AUTOSAR XML (schema 00046)
package /MICROSAR/BswM_swc
  6 x mode declaration group, all with category=EXPLICIT_ORDER:
    ESH_RunRequest: initial-mode=RELEASED, on-transition-value=2
      mode RELEASED: value=0
      mode REQUESTED: value=1
    BswMRteShutdownReqMode: initial-mode=BswMReqNone, on-transition-value=5
      5 x mode:
        BswMReqSleep: value=1
        BswMReqShutdown: value=3
        BswMReqShutdownEmergency: value=4
        BswMReqNone: value=0
        BswMReqSleepEmergency: value=5
    ESH_Mode: initial-mode=STARTUP, on-transition-value=6
      6 x mode:
        STARTUP: value=0
        RUN: value=1
        POSTRUN: value=2
        WAKEUP: value=3
        SHUTDOWN: value=4
        NVMPROCESS: value=5
    BswMRteVehicleTypeOptionChoose: initial-mode=FUEL, on-transition-value=2
      mode FUEL: value=0
      mode EV: value=1
    BswMRteModeBusStateReq: initial-mode=BLOCK_STATE, on-transition-value=2
      mode BLOCK_STATE: value=1
      mode UNBLOCK_STATE: value=0
    BswMRteModeVolEnable: initial-mode=Vol_Disable, on-transition-value=2
      mode Vol_Disable: value=0
      mode Vol_Enable: value=1
  data type mapping set BswMMappingSet  # Contains Mapping for ModeDeclarations Groups which are provided by BswM.
    mode-request-type-maps:
      implementation-data-type=BswM_ESH_Mode, mode-group=ESH_Mode
      implementation-data-type=BswM_ESH_RunRequest, mode-group=ESH_RunRequest
      implementation-data-type=BswM_BswMRteShutdownReqMode, mode-group=BswMRteShutdownReqMode
      implementation-data-type=BswM_BswMRteVehicleTypeOptionChoose, mode-group=BswMRteVehicleTypeOptionChoose
      implementation-data-type=BswM_BswMRteModeBusStateReq, mode-group=BswMRteModeBusStateReq
      implementation-data-type=BswM_BswMRteModeVolEnable, mode-group=BswMRteModeVolEnable
package /MICROSAR/BswM_swc/DataTypes
  6 x impl type, all with category=TYPE_REFERENCE, range raw 0..255, implementation-data-type=uint8:
    BswM_ESH_RunRequest: compu {0=RELEASED, 1=REQUESTED}  # Unique value for each user
    BswM_BswMRteShutdownReqMode: compu {1=BswMReqSleep, 3=BswMReqShutdown, 4=BswMReqShutdownEmergency, 0=BswMReqNone, 5=BswMReqSleepEmergency}  # Unique value for each user
    BswM_ESH_Mode: compu {0=STARTUP, 1=RUN, 2=POSTRUN, 3=WAKEUP, 4=SHUTDOWN, 5=NVMPROCESS}  # Unique value for each user
    BswM_BswMRteVehicleTypeOptionChoose: compu {0=FUEL, 1=EV}  # Unique value for each user
    BswM_BswMRteModeBusStateReq: compu {1=BLOCK_STATE, 0=UNBLOCK_STATE}  # Unique value for each user
    BswM_BswMRteModeVolEnable: compu {0=Vol_Disable, 1=Vol_Enable}  # Unique value for each user
package /MICROSAR/BswM_swc/Interfaces
  mode switch interface BswM_MSI_ESH_Mode: is-service=true, service-kind=BASIC-SOFTWARE-MODE-MANAGER
    mode group BswM_MDGP_ESH_Mode: type=ESH_Mode
  sender receiver interface BswM_SRI_BswM_MSI_ESH_Mode_BswM_MDGP_ESH_Mode: is-service=true, service-kind=BASIC-SOFTWARE-MODE-MANAGER
    data requestedMode: type=BswM_ESH_Mode
  mode switch interface BswM_MSI_ESH_RunRequest: is-service=true, service-kind=BASIC-SOFTWARE-MODE-MANAGER
    mode group BswM_MDGP_ESH_RunRequest: type=ESH_RunRequest
  sender receiver interface BswM_SRI_BswM_MSI_ESH_RunRequest_BswM_MDGP_ESH_RunRequest: is-service=true, service-kind=BASIC-SOFTWARE-MODE-MANAGER
    data requestedMode: type=BswM_ESH_RunRequest
  mode switch interface BswM_MSI_BswMRteShutdownReqMode: is-service=true, service-kind=BASIC-SOFTWARE-MODE-MANAGER
    mode group BswM_MDGP_BswMRteShutdownReqMode: type=BswMRteShutdownReqMode
  sender receiver interface BswM_SRI_BswM_MSI_BswMRteShutdownReqMode_BswM_MDGP_BswMRteShutdownReqMode: is-service=true, service-kind=BASIC-SOFTWARE-MODE-MANAGER
    data requestedMode: type=BswM_BswMRteShutdownReqMode
  mode switch interface BswM_MSI_BswMRteVehicleTypeOptionChoose: is-service=true, service-kind=BASIC-SOFTWARE-MODE-MANAGER
    mode group BswM_MDGP_BswMRteVehicleTypeOptionChoose: type=BswMRteVehicleTypeOptionChoose
  sender receiver interface BswM_SRI_BswM_MSI_BswMRteVehicleTypeOptionChoose_BswM_MDGP_BswMRteVehicleTypeOptionChoose: is-service=true, service-kind=BASIC-SOFTWARE-MODE-MANAGER
    data requestedMode: type=BswM_BswMRteVehicleTypeOptionChoose
  mode switch interface BswM_MSI_BswMRteModeBusStateReq: is-service=true, service-kind=BASIC-SOFTWARE-MODE-MANAGER
    mode group BswM_MDGP_BswMRteModeBusStateReq: type=BswMRteModeBusStateReq
  sender receiver interface BswM_SRI_BswM_MSI_BswMRteModeBusStateReq_BswM_MDGP_BswMRteModeBusStateReq: is-service=true, service-kind=BASIC-SOFTWARE-MODE-MANAGER
    data requestedMode: type=BswM_BswMRteModeBusStateReq
  mode switch interface BswM_MSI_BswMRteModeVolEnable: is-service=true, service-kind=BASIC-SOFTWARE-MODE-MANAGER
    mode group BswM_MDGP_BswMRteModeVolEnable: type=BswMRteModeVolEnable
  sender receiver interface BswM_SRI_BswM_MSI_BswMRteModeVolEnable_BswM_MDGP_BswMRteModeVolEnable: is-service=true, service-kind=BASIC-SOFTWARE-MODE-MANAGER
    data requestedMode: type=BswM_BswMRteModeVolEnable
package /MICROSAR/BswM_swc/ComponentTypes
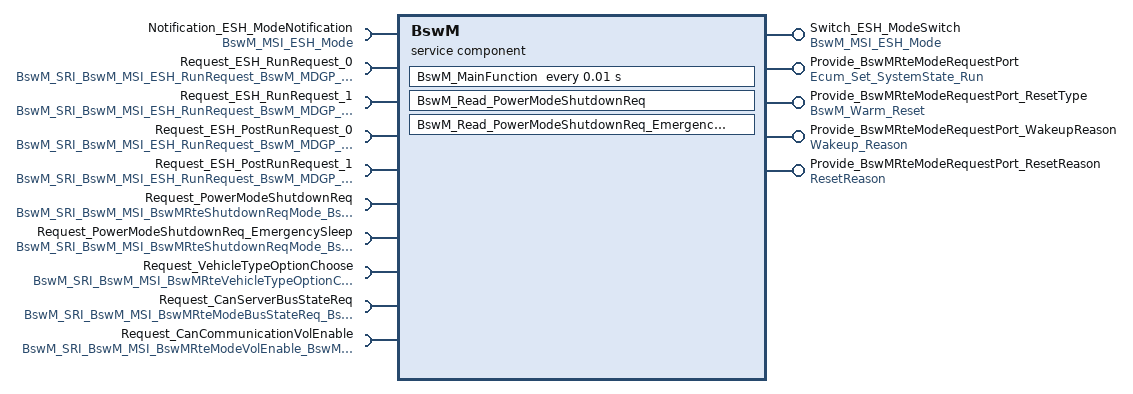
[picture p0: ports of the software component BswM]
  service sw component type BswM: category=SERVICE_COMPONENT
    provide port Switch_ESH_ModeSwitch: provided-interface=BswM_MSI_ESH_Mode
    6 x require port:
      Notification_ESH_ModeNotification: required-interface=BswM_MSI_ESH_Mode
      Request_ESH_RunRequest_0: nonqueued-receiver-com-spec{data-element=BswM_SRI_BswM_MSI_ESH_RunRequest_BswM_MDGP_ESH_RunRequest/requestedMode, handle-out-of-range-status=SILENT, init-value=RELEASED}, required-interface=BswM_SRI_BswM_MSI_ESH_RunRequest_BswM_MDGP_ESH_RunRequest
      Request_ESH_RunRequest_1: nonqueued-receiver-com-spec{data-element=BswM_SRI_BswM_MSI_ESH_RunRequest_BswM_MDGP_ESH_RunRequest/requestedMode, handle-out-of-range-status=SILENT, init-value=RELEASED}, required-interface=BswM_SRI_BswM_MSI_ESH_RunRequest_BswM_MDGP_ESH_RunRequest
      Request_ESH_PostRunRequest_0: nonqueued-receiver-com-spec{data-element=BswM_SRI_BswM_MSI_ESH_RunRequest_BswM_MDGP_ESH_RunRequest/requestedMode, handle-out-of-range-status=SILENT, init-value=RELEASED}, required-interface=BswM_SRI_BswM_MSI_ESH_RunRequest_BswM_MDGP_ESH_RunRequest
      Request_ESH_PostRunRequest_1: nonqueued-receiver-com-spec{data-element=BswM_SRI_BswM_MSI_ESH_RunRequest_BswM_MDGP_ESH_RunRequest/requestedMode, handle-out-of-range-status=SILENT, init-value=RELEASED}, required-interface=BswM_SRI_BswM_MSI_ESH_RunRequest_BswM_MDGP_ESH_RunRequest
      Request_PowerModeShutdownReq: nonqueued-receiver-com-spec{data-element=BswM_SRI_BswM_MSI_BswMRteShutdownReqMode_BswM_MDGP_BswMRteShutdownReqMode/requestedMode, handle-out-of-range-status=SILENT, init-value=BswMReqNone}, required-interface=BswM_SRI_BswM_MSI_BswMRteShutdownReqMode_BswM_MDGP_BswMRteShutdownReqMode
    provide port Provide_BswMRteModeRequestPort: nonqueued-sender-com-spec{data-element=Element, init-value=FALSE}, provided-interface=Ecum_Set_SystemState_Run
    require port Request_PowerModeShutdownReq_EmergencySleep: nonqueued-receiver-com-spec{data-element=BswM_SRI_BswM_MSI_BswMRteShutdownReqMode_BswM_MDGP_BswMRteShutdownReqMode/requestedMode, handle-out-of-range-status=SILENT, init-value=BswMReqNone}, required-interface=BswM_SRI_BswM_MSI_BswMRteShutdownReqMode_BswM_MDGP_BswMRteShutdownReqMode
    provide port Provide_BswMRteModeRequestPort_ResetType: nonqueued-sender-com-spec{data-element=Element, init-value=FALSE}, provided-interface=BswM_Warm_Reset
    provide port Provide_BswMRteModeRequestPort_WakeupReason: nonqueued-sender-com-spec{data-element=WakeupSource, init-value=value0}, provided-interface=Wakeup_Reason
    provide port Provide_BswMRteModeRequestPort_ResetReason: nonqueued-sender-com-spec{data-element=ResetSource, init-value=init}, provided-interface=ResetReason
    require port Request_VehicleTypeOptionChoose: nonqueued-receiver-com-spec{data-element=BswM_SRI_BswM_MSI_BswMRteVehicleTypeOptionChoose_BswM_MDGP_BswMRteVehicleTypeOptionChoose/requestedMode, handle-out-of-range-status=SILENT, init-value=FUEL}, required-interface=BswM_SRI_BswM_MSI_BswMRteVehicleTypeOptionChoose_BswM_MDGP_BswMRteVehicleTypeOptionChoose
    require port Request_CanServerBusStateReq: nonqueued-receiver-com-spec{data-element=BswM_SRI_BswM_MSI_BswMRteModeBusStateReq_BswM_MDGP_BswMRteModeBusStateReq/requestedMode, handle-out-of-range-status=SILENT, init-value=BLOCK_STATE}, required-interface=BswM_SRI_BswM_MSI_BswMRteModeBusStateReq_BswM_MDGP_BswMRteModeBusStateReq
    require port Request_CanCommunicationVolEnable: nonqueued-receiver-com-spec{data-element=BswM_SRI_BswM_MSI_BswMRteModeVolEnable_BswM_MDGP_BswMRteModeVolEnable/requestedMode, handle-out-of-range-status=SILENT, init-value=Vol_Disable}, required-interface=BswM_SRI_BswM_MSI_BswMRteModeVolEnable_BswM_MDGP_BswMRteModeVolEnable
    behavior BswMInternalBehavior: data-type-mapping=BswMMappingSet, handle-termination-and-restart=NO-SUPPORT, included-data-type-set=data-type=[BswM_ESH_Mode, BswM_ESH_RunRequest, BswM_BswMRteShutdownReqMode, BswM_BswMRteVehicleTypeOptionChoose, BswM_BswMRteModeBusStateReq, BswM_BswMRteModeVolEnable]
      timing event Timer_BswM_MainFunction: start-on-event=BswM_MainFunction, period=0.01
      data received event DataReceivedEvent_BswM_Read_PowerModeShutdownReq_Request_PowerModeShutdownReq_requestedMode: start-on-event=BswM_Read_PowerModeShutdownReq, data=Request_PowerModeShutdownReq.requestedMode
      data received event DataReceivedEvent_BswM_Read_PowerModeShutdownReq_EmergencySleep_Request_PowerModeShutdownReq_EmergencySleep_requestedMode: start-on-event=BswM_Read_PowerModeShutdownReq_EmergencySleep, data=Request_PowerModeShutdownReq_EmergencySleep.requestedMode
      port-api-options:
        enable-take-address=true, indirect-api=false, port=Switch_ESH_ModeSwitch
        enable-take-address=true, indirect-api=false, port=Notification_ESH_ModeNotification
        enable-take-address=true, indirect-api=false, port=Request_ESH_RunRequest_0
        enable-take-address=true, indirect-api=false, port=Request_ESH_RunRequest_1
        enable-take-address=true, indirect-api=false, port=Request_ESH_PostRunRequest_0
        enable-take-address=true, indirect-api=false, port=Request_ESH_PostRunRequest_1
        enable-take-address=true, indirect-api=false, port=Request_PowerModeShutdownReq
        enable-take-address=true, indirect-api=false, port=Request_PowerModeShutdownReq_EmergencySleep
        enable-take-address=true, indirect-api=false, port=Request_VehicleTypeOptionChoose
        enable-take-address=true, indirect-api=false, port=Request_CanServerBusStateReq
        enable-take-address=true, indirect-api=false, port=Provide_BswMRteModeRequestPort
        enable-take-address=true, indirect-api=false, port=Provide_BswMRteModeRequestPort_ResetType
        enable-take-address=true, indirect-api=false, port=Provide_BswMRteModeRequestPort_WakeupReason
        enable-take-address=true, indirect-api=false, port=Provide_BswMRteModeRequestPort_ResetReason
        enable-take-address=true, indirect-api=false, port=Request_CanCommunicationVolEnable
      runnable BswM_MainFunction: mode-access-point=Notification_ESH_ModeNotification.BswM_MDGP_ESH_Mode
        data-receive-point-by-arguments:
          7 x access:
            DataReceivePointBswM_MainFunction_Request_ESH_RunRequest_0_requestedMode: accessed-variable=Request_ESH_RunRequest_0.requestedMode
            DataReceivePointBswM_MainFunction_Request_ESH_RunRequest_1_requestedMode: accessed-variable=Request_ESH_RunRequest_1.requestedMode
            DataReceivePointBswM_MainFunction_Request_ESH_PostRunRequest_0_requestedMode: accessed-variable=Request_ESH_PostRunRequest_0.requestedMode
            DataReceivePointBswM_MainFunction_Request_ESH_PostRunRequest_1_requestedMode: accessed-variable=Request_ESH_PostRunRequest_1.requestedMode
            DataReceivePointBswM_MainFunction_Request_VehicleTypeOptionChoose_requestedMode: accessed-variable=Request_VehicleTypeOptionChoose.requestedMode
            DataReceivePointBswM_MainFunction_Request_CanServerBusStateReq_requestedMode: accessed-variable=Request_CanServerBusStateReq.requestedMode
            DataReceivePointBswM_MainFunction_Request_CanCommunicationVolEnable_requestedMode: accessed-variable=Request_CanCommunicationVolEnable.requestedMode
        data-send-points:
          4 x access:
            DataSendPointBswM_MainFunction_Provide_BswMRteModeRequestPort_Element: accessed-variable=Provide_BswMRteModeRequestPort.Element
            DataSendPointBswM_MainFunction_Provide_BswMRteModeRequestPort_ResetType_Element: accessed-variable=Provide_BswMRteModeRequestPort_ResetType.Element
            DataSendPointBswM_MainFunction_Provide_BswMRteModeRequestPort_WakeupReason_WakeupSource: accessed-variable=Provide_BswMRteModeRequestPort_WakeupReason.WakeupSource
            DataSendPointBswM_MainFunction_Provide_BswMRteModeRequestPort_ResetReason_ResetSource: accessed-variable=Provide_BswMRteModeRequestPort_ResetReason.ResetSource
        mode switch point ModeSwitchPointBswM_MainFunction_Switch_ESH_ModeSwitch_BswM_MDGP_ESH_Mode: mode-group=Switch_ESH_ModeSwitch.BswM_MDGP_ESH_Mode
      runnable BswM_Read_PowerModeShutdownReq: can-be-invoked-concurrently=true
        data-receive-point-by-arguments:
          access DataReceivePointBswM_Read_PowerModeShutdownReq_Request_PowerModeShutdownReq_requestedMode: accessed-variable=Request_PowerModeShutdownReq.requestedMode
      runnable BswM_Read_PowerModeShutdownReq_EmergencySleep: can-be-invoked-concurrently=true
        data-receive-point-by-arguments:
          access DataReceivePointBswM_Read_PowerModeShutdownReq_EmergencySleep_Request_PowerModeShutdownReq_EmergencySleep_requestedMode: accessed-variable=Request_PowerModeShutdownReq_EmergencySleep.requestedMode
  swc implementation BswMImplementation: programming-language=C, behavior=BswMInternalBehavior
